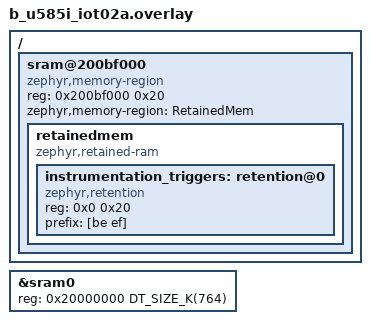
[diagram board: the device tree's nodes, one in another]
/*
 * Copyright 2023 Linaro
 *
 * SPDX-License-Identifier: Apache-2.0
 */

#include <common/mem.h>

/ {
	sram@200bf000 {
		compatible = "zephyr,memory-region", "mmio-sram";
		reg = <0x200bf000 0x20>;
		zephyr,memory-region = "RetainedMem";
		status = "okay";

		retainedmem {
			compatible = "zephyr,retained-ram";
			#address-cells = <1>;
			#size-cells = <1>;
			status = "okay";

			instrumentation_triggers: retention@0 {
				compatible = "zephyr,retention";

				reg = <0x0 0x20>;

				prefix = [be ef];
				status = "okay";
			};
		};
	};
};

&sram0 {
	reg = <0x20000000 DT_SIZE_K(764)>;
};
